# MKE15D7 register map
File version: 1.6
Registers are 32-bit, read-write, reset 0x0 unless marked. A register's access mark holds for its fields unless they carry their own. Offsets are from the block's base; [hi:lo] are bit positions; {n}, {i} and the like mark numbered series; 'fields as' and 'values as' point back to an identical list.

## SIM — System Integration Module
Base 0x40032000; register names take the prefix SIM_
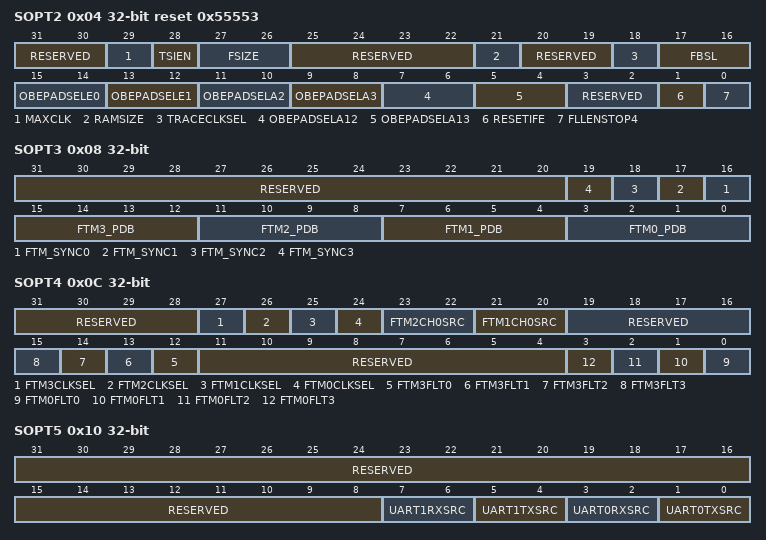
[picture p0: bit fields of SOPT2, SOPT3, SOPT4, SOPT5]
0x04 SOPT2 reset 0x55553 — System Options Register 2
  [31:30] RESERVED ro
  [29] MAXCLK ro
    0=Maximum clock in the system is 36 MHz; 1=Maximum clock in the system is 72 MHz
  [28] TSIEN ro
    0=TSI is not available in the device; 1=TSI is available in the device
  [27:26] FSIZE ro — The flash size of the device.
    0=128 KB; 1=192 KB; 2=256 KB; 3=256KB
  [25:22] RESERVED ro
  [21] RAMSIZE ro — The RAM size in the device.
    0=RAM size is 16 KB in the device. ( 8 KB Upper SRAM. 8 KB Lower SRAM).; 1=RAM size is 24 KB in the device. (16 KB Upper SRAM. 8 KB Lower SRAM).
  [20:19] RESERVED ro
  [18] TRACECLKSEL — Debug trace clock select
    0=ICSOUTCLK; 1=Core/system clock
  [17:16] FBSL — FlexBus security level
    0=All off-chip accesses (instruction and data) via the FlexBus are disallowed; 1=All off-chip accesses (instruction and data) via the FlexBus are disallowed; 2=Off-chip instruction accesses are disallowed. Data accesses are allowed.; 3=Off-chip instruction accesses and data accesses are allowed
  [15:14] OBEPADSELE0
    0=5 mA drive strength for pad PTE0; 1=5 mA drive strength for pad PTE0; 2=15 mA drive strength for pad PTE0; 3=20 mA drive strength for pad PTE0
  [13:12] OBEPADSELE1
    0=5 mA drive strength for pad PTE1; 1=5 mA drive strength for pad PTE1; 2=15 mA drive strength for pad PTE1; 3=20 mA drive strength for pad PTE1
  [11:10] OBEPADSELA2
    0=5 mA drive strength for pad PTA2; 1=5 mA drive strength for pad PTA2; 2=15 mA drive strength for pad PTA2; 3=20 mA drive strength for pad PTA2
  [9:8] OBEPADSELA3
    0=5 mA drive strength for pad PTA3; 1=5 mA drive strength for pad PTA3; 2=15 mA drive strength for pad PTA3; 3=20 mA drive strength for pad PTA3
  [7:6] OBEPADSELA12
    0=5 mA drive strength for pad PTA12; 1=5 mA drive strength for pad PTA12; 2=15 mA drive strength for pad PTA12; 3=20 mA drive strength for pad PTA12
  [5:4] OBEPADSELA13
    0=5 mA drive strength for pad PTA13; 1=5 mA drive strength for pad PTA13; 2=15 mA drive strength for pad PTA13; 3=20 mA drive strength for pad PTA13
  [3:2] RESERVED ro
  [1] RESETIFE
    0=Filter of Reset pad is disabled; 1=Filter of Reset pad is enabled
  [0] FLLENSTOP4
    0=FLL is disabled in STOP4 mode; 1=FLL is enbled in STOP4 mode
0x08 SOPT3 — System Options Register 3
  [31:20] RESERVED ro, [n+16] FTM_SYNC{n} (n=0..3), [4n+3:4n] FTM{n}_PDB (n=0..3)
0x0C SOPT4 — System Options Register 4
  [31:28] RESERVED ro
  [27] FTM3CLKSEL — FlexTimer 3 External Clock Pin Select
    0=FTM3 external clock driven by FTM_CLK0 pin; 1=FTM3 external clock driven by FTM_CLK1 pin
  [26] FTM2CLKSEL — FlexTimer 2 External Clock Pin Select
    0=FTM2 external clock driven by FTM_CLK0 pin; 1=FTM2 external clock driven by FTM_CLK1 pin
  [25] FTM1CLKSEL — FTM1 External Clock Pin Select
    0=FTM_CLK0 pin; 1=FTM_CLK1 pin
  [24] FTM0CLKSEL — FlexTimer 0 External Clock Pin Select
    0=FTM_CLK0 pin; 1=FTM_CLK1 pin
  [23:22] FTM2CH0SRC — FTM2 channel 0 input capture source select
    0=FTM2_CH0 signal; 1=CMP1 output; 2=CMP2 output; 3=CMP3 output
  [21:20] FTM1CH0SRC — FTM1 channel 0 input capture source select
    0=FTM1_CH0 signal; 1=CMP0 output; 2=CMP1 output; 3=CMP2 output
  [19:16] RESERVED ro
  [n+12] FTM3FLT{n} (n=0..3) — FTM3 Fault {n} Select
    0=FTM3_FLT{n} pin; 1=CMP{n} out
  [11:4] RESERVED ro
  [n] FTM0FLT{n} (n=0..3) — FTM0 Fault {n} Select
    0=FTM0_FLT{n} pin; 1=CMP{n} out
0x10 SOPT5 — System Options Register 5
  [31:8] RESERVED ro
  [7:6] UART1RXSRC — UART 1 receive data source select
    0=UART1_RX pin; 1=CMP0; 2=CMP1
  [5:4] UART1TXSRC — UART 1 transmit data source select
    0=UART1_TX pin; 1=UART1_TX pin modulated with FTM1 channel 0 output; 2=UART1_TX pin modulated with FTM2 channel 0 output
  [3:2] UART0RXSRC — UART 0 receive data source select
    0=UART0_RX pin; 1=CMP0; 2=CMP1
  [1:0] UART0TXSRC — UART 0 transmit data source select
    0=UART0_TX pin; 1=UART0_TX pin modulated with FTM1 channel 0 output; 2=UART0_TX pin modulated with FTM2 channel 0 output
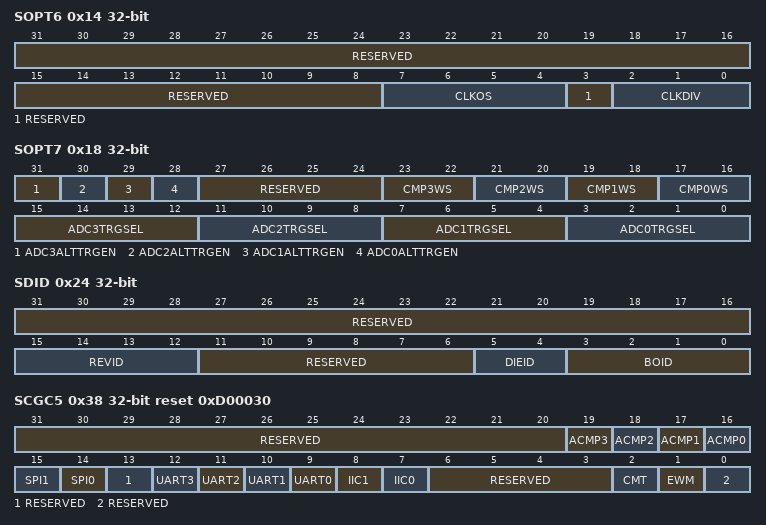
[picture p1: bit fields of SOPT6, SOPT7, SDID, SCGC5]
0x14 SOPT6 — System Options Register 6
  [31:8] RESERVED ro
  [7:4] CLKOS — Clock source select
    0=bus_clk; 1=flash_clk; 2=ICSIRCLK; 3=ICSFFCLK; 4=ICSOUT; 5=ICSDCLK; 6=ICSLCLK; 7=OSCOUT; 8=LPOCLK; 9=flex_bus clock; 10=platform_clk
  [3] RESERVED ro
  [2:0] CLKDIV
    0=Divided by 1; 1=Divided by 2; 2=Divided by 4; 3=Divided by 8; 4=Divided by 16
0x18 SOPT7 — System Options Register 7
  [31] ADC3ALTTRGEN — ADC3 alternate trigger enable
    0=PDB trigger selected for ADC3; 1=Alternate trigger selected for ADC3 as defined by ADC3TRGSEL
  [30] ADC2ALTTRGEN — ADC2 alternate trigger enable
    0=PDB trigger selected for ADC2; 1=Alternate trigger selected for ADC2 as defined by ADC2TRGSEL
  [29] ADC1ALTTRGEN — ADC1 alternate trigger enable
    0=PDB trigger selected for ADC1; 1=Alternate trigger selected for ADC1
  [28] ADC0ALTTRGEN — ADC0 alternate trigger enable
    0=PDB trigger selected for ADC0; 1=Alternate trigger selected for ADC0
  [27:24] RESERVED ro
  [2n+17:2n+16] CMP{n}WS (n=0..3) — CMP{n} windows select
    {v}=PDB{v} (v=0..3)
  [4n+3:4n] ADC{n}TRGSEL (n=0..3) — ADC{n} trigger select
    0=PDB external trigger pin input (PDB0_EXTRG); 1=High speed comparator 0 output; 2=High speed comparator 1 output; 3=High speed comparator 2 output; {v}=PIT trigger {v-4} (v=4..7); {v}=FTM{v-8} trigger (v=8..11); 12=High speed comparator 3 output; 13=RTC interrupt
0x24 SDID ro reset not defined — System Device Identification Register
  [31:16] RESERVED
  [15:12] REVID — Device revision number
  [11:6] RESERVED
  [5:4] DIEID — Device family identification
  [3:0] BOID — Pincount identification
    4=44-pin; 5=64-pin; 6=80-pin; 8=100-pin
0x38 SCGC5 reset 0xD00030 — System Clock Gating Control Register 5
  [31:20] RESERVED ro
  [n+16] ACMP{n} (n=0..3) — ACMP{n} Clock Gate Control
    0=Clock disabled; 1=Clock enabled
  [15] SPI1 — SPI1 Clock Gate Control
    0=Clock disabled; 1=Clock enabled
  [14] SPI0 — SPI0 Clock Gate Control
    0=Clock disabled; 1=Clock enabled
  [13] RESERVED ro
  [n+9] UART{n} (n=0..3) — UART{n} Clock Gate Control
    0=Clock disabled; 1=Clock enabled
  [8] IIC1 — IIC1 Clock Gate Control
    0=Clock disabled; 1=Clock enabled
  [7] IIC0 — IIC0 Clock Gate Control
    0=Clock disabled; 1=Clock enabled
  [6:3] RESERVED ro
  [2] CMT — CMT Clock Gate Control
    0=Clock disabled; 1=Clock enabled
  [1] EWM — EWM Clock Gate Control
    0=Clock disabled; 1=Clock enabled
  [0] RESERVED ro
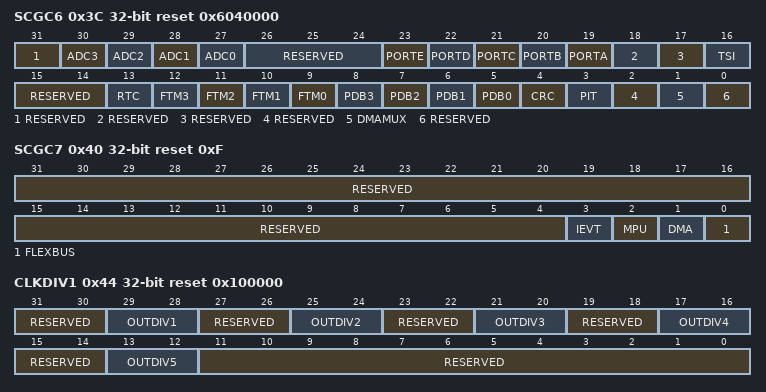
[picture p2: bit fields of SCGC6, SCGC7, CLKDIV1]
0x3C SCGC6 reset 0x6040000 — System Clock Gating Control Register 6
  [31] RESERVED ro
  [n+27] ADC{n} (n=0..3) — ADC{n} Clock Gate Control
    0=Clock disabled; 1=Clock enabled
  [26:24] RESERVED ro
  [23] PORTE — Port E Clock Gate Control
    0=Clock disabled; 1=Clock enabled
  [22] PORTD — Port D Clock Gate Control
    0=Clock disabled; 1=Clock enabled
  [21] PORTC — Port C Clock Gate Control
    0=Clock disabled; 1=Clock enabled
  [20] PORTB — Port B Clock Gate Control
    0=Clock disabled; 1=Clock enabled
  [19] PORTA — Port A Clock Gate Control
    0=Clock disabled; 1=Clock enabled
  [18] RESERVED ro
  [17] RESERVED ro
  [16] TSI — TSI Clock Gate Control
    0=Clock disabled; 1=Clock enabled
  [15:14] RESERVED ro
  [13] RTC — RTC Clock Gate Control
    0=Clock disabled; 1=Clock enabled
  [n+9] FTM{n} (n=0..3) — FTM{n} Clock Gate Control
    0=Clock disabled; 1=Clock enabled
  [n+5] PDB{n} (n=0..3) — PDB{n} Clock Gate Control
    0=Clock disabled; 1=Clock enabled
  [4] CRC — CRC Clock Gate Control
    0=Clock disabled; 1=Clock enabled
  [3] PIT — PIT Clock Gate Control
    0=Clock disabled; 1=Clock enabled
  [2] RESERVED ro
  [1] DMAMUX — DMAMUX Clock Gate Control
    0=Clock disabled; 1=Clock enabled
  [0] RESERVED ro
0x40 SCGC7 reset 0xF — System Clock Gating Control Register 7
  [31:4] RESERVED ro
  [3] IEVT — IEVT Clock Gate Control
    0=Clock disabled; 1=Clock enabled
  [2] MPU — MPU Clock Gate Control
    0=Clock disabled; 1=Clock enabled
  [1] DMA — DMA Clock Gate Control
    0=Clock disabled; 1=Clock enabled
  [0] FLEXBUS — FlexBus Clock Gate Control
    0=Clock disabled; 1=Clock enabled
0x44 CLKDIV1 reset 0x100000 — System Clock Divider Register 1
  [31:30] RESERVED ro
  [29:28] OUTDIV1 — Clock 1 output divider value
    0=ICSOUT Divided by 1; 1=ICSOUT Divided by 2; 3=ICSOUT Divided by 4
  [27:26] RESERVED ro
  [25:24] OUTDIV2 — Clock 2 output divider value
    0=ICSOUT divided by 2; 1=ICSOUT divided by 4; 3=ICSOUT divided by 8
  [23:22] RESERVED ro
  [21:20] OUTDIV3 — Clock 3 output divider value
    0=ICSOUT divided by 4, it is valid only when Maxclk = 36 MHz; 1=ICSOUT divided by 8; 3=ICSOUT divided by 16, it is valid only when Maxclk = 36 MHz
  [19:18] RESERVED ro
  [17:16] OUTDIV4 — Clock 4 output divider value
    values as OUTDIV2
  [15:14] RESERVED ro
  [13:12] OUTDIV5 — Clock 5 output divider value
    0=ICSOUT divided by 1; 1=ICSOUT divided by 2; 3=ICSOUT divided by 4
  [11:0] RESERVED ro
0x54 UIDH ro reset not defined — Unique Identification Register High
  [31:0] UID — Unique Identification
0x58 UIDMH ro reset not defined — Unique Identification Register Mid-High
  [31:0] UID — Unique Identification
0x5C UIDML ro reset not defined — Unique Identification Register Mid Low
  [31:0] UID — Unique Identification (bits [63:32]
0x60 UIDL ro reset not defined — Unique Identification Register Low
  [31:0] UID — Unique Identification
